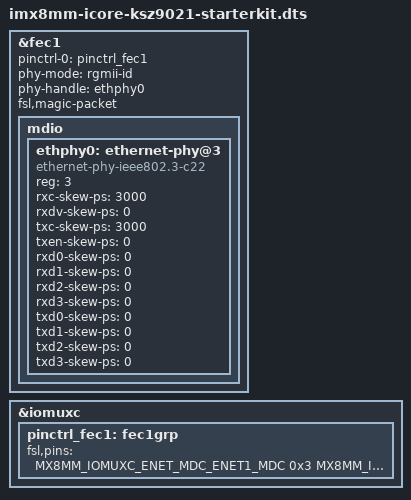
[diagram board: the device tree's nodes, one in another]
// SPDX-License-Identifier: (GPL-2.0+ OR MIT)
/*
 * Copyright 2020 NXP
 */

/dts-v1/;

#include "imx8mm-icore-starterkit.dts"


&fec1 {
	pinctrl-names = "default";
	pinctrl-0 = <&pinctrl_fec1>;
	phy-mode = "rgmii-id";
	phy-handle = <&ethphy0>;
	fsl,magic-packet;
	status = "okay";

	/delete-node/ mdio;

	mdio {
		#address-cells = <1>;
		#size-cells = <0>;

		ethphy0: ethernet-phy@3 {
			compatible = "ethernet-phy-ieee802.3-c22";
			reg = <3>;
			rxc-skew-ps = <3000>;
			rxdv-skew-ps = <0>;
			txc-skew-ps = <3000>;
			txen-skew-ps = <0>;
			rxd0-skew-ps = <0>;
			rxd1-skew-ps = <0>;
			rxd2-skew-ps = <0>;
			rxd3-skew-ps = <0>;
			txd0-skew-ps = <0>;
			txd1-skew-ps = <0>;
			txd2-skew-ps = <0>;
			txd3-skew-ps = <0>;
		};
	};
};

&iomuxc {
	pinctrl_fec1: fec1grp {
		fsl,pins = <
			MX8MM_IOMUXC_ENET_MDC_ENET1_MDC                 0x3
			MX8MM_IOMUXC_ENET_MDIO_ENET1_MDIO               0x3
			MX8MM_IOMUXC_ENET_TD3_ENET1_RGMII_TD3           0x14
			MX8MM_IOMUXC_ENET_TD2_ENET1_RGMII_TD2           0x14
			MX8MM_IOMUXC_ENET_TD1_ENET1_RGMII_TD1           0x14
			MX8MM_IOMUXC_ENET_TD0_ENET1_RGMII_TD0           0x14
			MX8MM_IOMUXC_ENET_RD3_ENET1_RGMII_RD3           0x91
			MX8MM_IOMUXC_ENET_RD2_ENET1_RGMII_RD2           0x91
			MX8MM_IOMUXC_ENET_RD1_ENET1_RGMII_RD1           0x91
			MX8MM_IOMUXC_ENET_RD0_ENET1_RGMII_RD0           0x91
			MX8MM_IOMUXC_ENET_TXC_ENET1_RGMII_TXC           0x14
			MX8MM_IOMUXC_ENET_RXC_ENET1_RGMII_RXC           0x91
			MX8MM_IOMUXC_ENET_RX_CTL_ENET1_RGMII_RX_CTL     0x91
			MX8MM_IOMUXC_ENET_TX_CTL_ENET1_RGMII_TX_CTL     0x14
		>;
	};
};
